# SIM3L167_C register map
File version: 1
CPU: 
Registers are 32-bit, read-write, reset 0x0 unless marked. A register's access mark holds for its fields unless they carry their own. Offsets are from the block's base; [hi:lo] are bit positions; {n}, {i} and the like mark numbered series.

## LPTIMER_0
Base 0x40038000
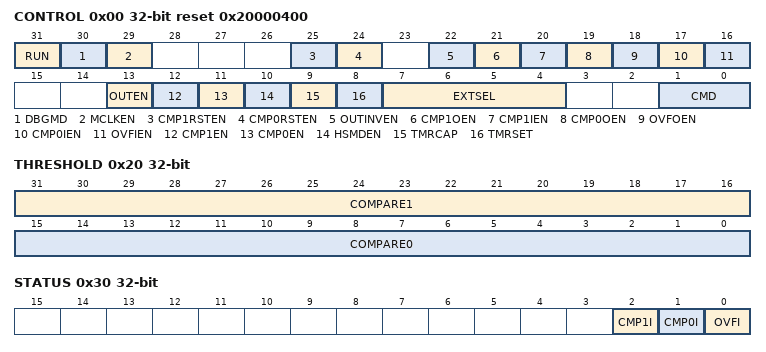
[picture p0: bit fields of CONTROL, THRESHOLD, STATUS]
0x00 CONTROL reset 0x20000400 — Module Control
  [31] RUN — Timer Run Control and Compare Threshold Enable.
    0=STOP (Stop the timer and disable the compare threshold.); 1=START (Start the timer running and enable the compare threshold.)
  [30] DBGMD — Low Power Timer Debug Mode.
    0=RUN (The Low Power Timer module will continue to operate while the core is halted in debug mode.); 1=HALT (A debug breakpoint will cause the Low Power Timer module to halt.)
  [29] MCLKEN — Low Power Timer Module Clock Enable.
    0=DISABLED (Disable the clock to the Low Power Timer module.); 1=ENABLED (Enable the clock to the Low Power Timer module.)
  [25] CMP1RSTEN — Timer Compare 1 Event Reset Enable.
    0=DISABLED (Timer compare 1 events do not reset the timer.); 1=ENABLED (Timer compare 1 events reset the timer.)
  [24] CMP0RSTEN — Timer Compare 0 Event Reset Enable.
    0=DISABLED (Timer compare 0 events do not reset the timer.); 1=ENABLED (Timer compare 0 events reset the timer.)
  [22] OUTINVEN — Output Inversion Enable.
    0=DISABLED (Do not invert the LPTIMER0 output.); 1=ENABLED (Invert the LPTIMER0 output.)
  [21] CMP1OEN — Timer Compare 1 Event Output Enable.
    0=DISABLED (Timer compare 1 events do not modify the Low Power Timer output.); 1=ENABLED (Timer compare 1 events set the Low Power Timer output to 1.)
  [20] CMP1IEN — Timer Compare 1 Event Interrupt Enable.
    0=DISABLED (Disable the timer compare 1 event interrupt.); 1=ENABLED (Enable the timer compare 1 event interrupt.)
  [19] CMP0OEN — Timer Compare 0 Event Output Enable.
    0=DISABLED (Timer compare 0 events do not modify the Low Power Timer output.); 1=ENABLED (Timer compare 0 events clear the Low Power Timer output to 0.)
  [18] OVFOEN — Timer Overflow Output Enable.
    0=DISABLED (Timer overflows do not modify the Low Power Timer output.); 1=ENABLED (Timer overflows set the Low Power Timer output to 1.)
  [17] CMP0IEN — Timer Compare 0 Event Interrupt Enable.
    0=DISABLED (Disable the timer compare 0 event interrupt.); 1=ENABLED (Enable the timer compare 0 event interrupt.)
  [16] OVFIEN — Timer Overflow Interrupt Enable.
    0=DISABLED (Disable the timer overflow interrupt.); 1=ENABLED (Enable the timer overflow interrupt.)
  [13] OUTEN — Output Enable.
    0=DISABLED (Disable the LPTIMER0 output.); 1=ENABLED (Enable the LPTIMER0 output.)
  [12] CMP1EN — Timer Compare 1 Threshold Enable.
    0=DISABLED; 1=ENABLED
  [11] CMP0EN — Timer Compare 0 Threshold Enable.
    0=DISABLED; 1=ENABLED
  [10] HSMDEN — High Speed Timer Access Mode Enable.
    0=DISABLED (Disable high speed timer access mode.); 1=ENABLED (Enable high speed timer access mode.)
  [9] TMRCAP — Timer Capture.
    1=SET (Writing a 1 to TMRCAP initiates a read of internal timer register into the COUNT register. This field is automatically cleared by hardware when the operation completes and does not need to be cleared by software.)
  [8] TMRSET — Timer Set.
    1=SET (Writing a 1 to TMRSET initiates a copy of the value from the COUNT register into the internal timer register. This field is automatically cleared by hardware when the copy is complete and does not need to be cleared by software.)
  [7:4] EXTSEL — External Trigger Source Select.
    {v}=LPTNT{v} (Select external trigger LPTnT{v}.) (v=0..15)
  [1:0] CMD — Count Mode.
    0=FREE (The timer is free running mode on the RTC timer clock (RTC0TCLK).); 1=RISING_EDGE (The timer is incremented on the rising edges of the selected external trigger (LPTnTx).); 2=FALLING_EDGE (The timer is incremented on the falling edges of the selected external trigger (LPTnTx).); 3=ANY_EDGE (The timer is incremented on both edges of the selected external trigger (LPTnTx).)
0x10 COUNT — Timer Value
  [15:0] TIMER — Timer Value.
0x20 THRESHOLD — Threshold Values
  [31:16] COMPARE1 — Timer Compare 1 Threshold Value.
  [15:0] COMPARE0 — Timer Compare 0 Threshold Value.
0x30 STATUS — Module Status
  [2] CMP1I — Timer Compare 1 Event Interrupt Flag.
    0=NOT_SET (A timer compare 1 event has not occurred.); 1=SET (A timer compare 1 event occurred.)
  [1] CMP0I — Timer Compare 0 Event Interrupt Flag.
    0=NOT_SET (A timer compare 0 event has not occurred.); 1=SET (A timer compare 0 event occurred.)
  [0] OVFI — Timer Overflow Interrupt Flag.
    0=NOT_SET (A timer overflow has not occurred.); 1=SET (A timer overflow occurred.)
